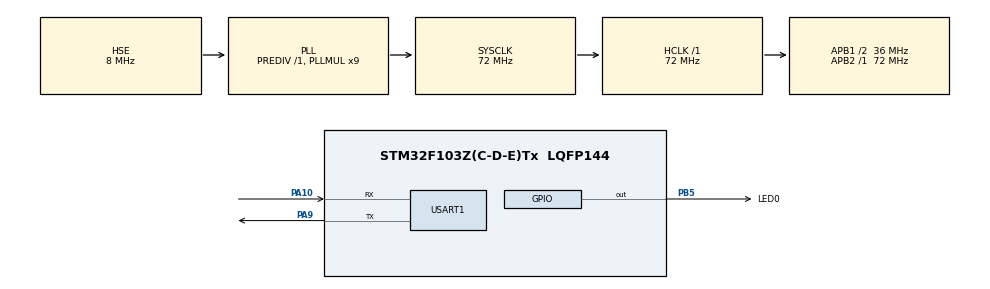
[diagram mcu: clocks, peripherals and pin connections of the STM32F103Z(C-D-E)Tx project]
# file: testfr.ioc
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FREERTOS.Tasks01=defaultTask,24,128,StartDefaultTask,Default,NULL,Dynamic,NULL,NULL
Mcu.Family=STM32F1
Mcu.Name=STM32F103Z(C-D-E)Tx
Mcu.Package=LQFP144
NVIC.PriorityGroup=NVIC_PRIORITYGROUP_4
NVIC.TIM4_IRQn=true\:15\:0\:false\:false\:true\:false\:false\:true\:true
NVIC.TimeBase=TIM4_IRQn
NVIC.TimeBaseIP=TIM4
NVIC.USART1_IRQn=true\:5\:0\:false\:false\:true\:true\:true\:true\:true
OSC_IN.Mode=HSE-External-Oscillator
OSC_IN.Signal=RCC_OSC_IN
OSC_OUT.Mode=HSE-External-Oscillator
OSC_OUT.Signal=RCC_OSC_OUT
PA10.Mode=Asynchronous
PA10.Signal=USART1_RX
PA13.Mode=Serial_Wire
PA13.Signal=SYS_JTMS-SWDIO
PA14.Mode=Serial_Wire
PA14.Signal=SYS_JTCK-SWCLK
PA9.Mode=Asynchronous
PA9.Signal=USART1_TX
PB5.GPIO_Label=LED0
PB5.Signal=GPIO_Output
ProjectManager.HeapSize=0x200
ProjectManager.StackSize=0x400
ProjectManager.TargetToolchain=Makefile
RCC.AHBFreq_Value=72000000
RCC.APB1CLKDivider=RCC_HCLK_DIV2
RCC.APB1Freq_Value=36000000
RCC.APB1TimFreq_Value=72000000
RCC.APB2Freq_Value=72000000
RCC.APB2TimFreq_Value=72000000
RCC.HCLKFreq_Value=72000000
RCC.PLLMUL=RCC_PLL_MUL9
RCC.PLLSourceVirtual=RCC_PLLSOURCE_HSE
RCC.SYSCLKFreq_VALUE=72000000
RCC.SYSCLKSource=RCC_SYSCLKSOURCE_PLLCLK
RCC.USBFreq_Value=72000000
USART1.VirtualMode=VM_ASYNC
VP_FREERTOS_VS_CMSIS_V2.Mode=CMSIS_V2
VP_SYS_VS_tim4.Mode=TIM4
board=custom

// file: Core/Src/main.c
/* USER CODE BEGIN Header */
/**
 ******************************************************************************
 * @file           : main.c
 * @brief          : Main program body
 ******************************************************************************
 * @attention
 *
 * Copyright (c) 2026 STMicroelectronics.
 * All rights reserved.
 *
 * This software is licensed under terms that can be found in the LICENSE file
 * in the root directory of this software component.
 * If no LICENSE file comes with this software, it is provided AS-IS.
 *
 ******************************************************************************
 */
/* USER CODE END Header */
#include "main.h"
#include "cmsis_os.h"
#include "usart.h"
#include "gpio.h"

/* USER CODE BEGIN Includes */
#include "iwdg_drv.h"
#include "rtc_drv.h"
/* USER CODE END Includes */

void SystemClock_Config(void);
void MX_FREERTOS_Init(void);

int main(void)
{

  /* USER CODE BEGIN 1 */
  SCB->VTOR = 0x08008000;
  /* USER CODE END 1 */

  /* MCU Configuration--------------------------------------------------------*/

  /* Reset of all peripherals, Initializes the Flash interface and the Systick. */
  HAL_Init();

  /* Configure the system clock */
  SystemClock_Config();

  /* Initialize all configured peripherals */
  MX_GPIO_Init();
  MX_USART1_UART_Init();
  /* USER CODE BEGIN 2 */
  IWDG_DRV_Init(2); /* Start independent watchdog (2s timeout) */
  /* USER CODE END 2 */
  /* RTC: only set time on first boot (backup domain lost) */
  if (RTC_DRV_Init() != HAL_OK)
  {
    RTC_DRV_SetDate(26, 6, 1, 0); /* 2026-06-01 Sunday */
    RTC_DRV_SetTime(21, 20, 0);   /* 21:18:00 */
  }
  /* Init scheduler */
  osKernelInitialize();

  /* Call init function for freertos objects (in cmsis_os2.c) */
  MX_FREERTOS_Init();

  /* Start scheduler */
  osKernelStart();

  /* We should never get here as control is now taken by the scheduler */

  /* Infinite loop */
  while (1)
  {

  }
}

void SystemClock_Config(void)
{
  RCC_OscInitTypeDef RCC_OscInitStruct = {0};
  RCC_ClkInitTypeDef RCC_ClkInitStruct = {0};

  /** Initializes the RCC Oscillators according to the specified parameters
   * in the RCC_OscInitTypeDef structure.
   */
  RCC_OscInitStruct.OscillatorType = RCC_OSCILLATORTYPE_HSE;
  RCC_OscInitStruct.HSEState = RCC_HSE_ON;
  RCC_OscInitStruct.HSEPredivValue = RCC_HSE_PREDIV_DIV1;
  RCC_OscInitStruct.HSIState = RCC_HSI_ON;
  RCC_OscInitStruct.PLL.PLLState = RCC_PLL_ON;
  RCC_OscInitStruct.PLL.PLLSource = RCC_PLLSOURCE_HSE;
  RCC_OscInitStruct.PLL.PLLMUL = RCC_PLL_MUL9;
  if (HAL_RCC_OscConfig(&RCC_OscInitStruct) != HAL_OK)
  {
    Error_Handler();
  }

  /** Initializes the CPU, AHB and APB buses clocks
   */
  RCC_ClkInitStruct.ClockType = RCC_CLOCKTYPE_HCLK | RCC_CLOCKTYPE_SYSCLK | RCC_CLOCKTYPE_PCLK1 | RCC_CLOCKTYPE_PCLK2;
  RCC_ClkInitStruct.SYSCLKSource = RCC_SYSCLKSOURCE_PLLCLK;
  RCC_ClkInitStruct.AHBCLKDivider = RCC_SYSCLK_DIV1;
  RCC_ClkInitStruct.APB1CLKDivider = RCC_HCLK_DIV2;
  RCC_ClkInitStruct.APB2CLKDivider = RCC_HCLK_DIV1;

  if (HAL_RCC_ClockConfig(&RCC_ClkInitStruct, FLASH_LATENCY_2) != HAL_OK)
  {
    Error_Handler();
  }
}

void HAL_TIM_PeriodElapsedCallback(TIM_HandleTypeDef *htim)
{
  if (htim->Instance == TIM4)
  {
    HAL_IncTick();
  }
}

void Error_Handler(void)
{
  __disable_irq();
  while (1)
  {
  }
}

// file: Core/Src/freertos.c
/* USER CODE BEGIN Header */
/**
 ******************************************************************************
 * File Name          : freertos.c
 * Description        : Code for freertos applications
 ******************************************************************************
 * @attention
 *
 * Copyright (c) 2026 STMicroelectronics.
 * All rights reserved.
 *
 * This software is licensed under terms that can be found in the LICENSE file
 * in the root directory of this software component.
 * If no LICENSE file comes with this software, it is provided AS-IS.
 *
 ******************************************************************************
 */
/* USER CODE END Header */

#include "FreeRTOS.h"
#include "task.h"
#include "main.h"
#include "cmsis_os.h"

/* USER CODE BEGIN Includes */
#include "key.h"
#include "usart.h"
#include "app_temp.h"
#include "app_lcd.h"
#include "iwdg_drv.h"
#include "cmsis_os2.h"
#include "breath_led.h"
#include "app_eeprom.h"
#include <stdio.h>
/* USER CODE END Includes */

/* USER CODE BEGIN Variables */
osMessageQueueId_t keyQueueHandle;
osMessageQueueAttr_t keyQueue_attributes = {
    .name = "keyQueue"
};

osMessageQueueId_t eepromQueueHandle;
osMessageQueueAttr_t eepromQueue_attributes = {
    .name = "eepromQueue"
};
/* USER CODE END Variables */
/* Definitions for defaultTask */
osThreadId_t defaultTaskHandle;
const osThreadAttr_t defaultTask_attributes = {
    .name = "defaultTask",
    .stack_size = 128 * 4,
    .priority = (osPriority_t)osPriorityNormal,
};

/* Definitions for keyTask */
osThreadId_t keyTaskHandle;
const osThreadAttr_t keyTask_attributes = {
    .name = "keyTask",
    .stack_size = 128 * 4,
    .priority = (osPriority_t)osPriorityNormal,
};
/* Definitions for tempTask */
osThreadId_t tempTaskHandle;
const osThreadAttr_t tempTask_attributes = {
    .name = "tempTask",
    .stack_size = 256 * 4,
    .priority = (osPriority_t)osPriorityLow,
};
/* Definitions for lcdTask */
osThreadId_t lcdTaskHandle;
const osThreadAttr_t lcdTask_attributes = {
    .name = "lcdTask",
    .stack_size = 512 * 4,
    .priority = (osPriority_t)osPriorityNormal,
};
/* Definitions for eepromTask */
osThreadId_t eepromTaskHandle;
const osThreadAttr_t eepromTask_attributes = {
    .name = "eepromTask",
    .stack_size = 128 * 4,
    .priority = (osPriority_t)osPriorityNormal,
};

void StartDefaultTask(void *argument);
void StartKeyTask(void *argument);
void StartTempTask(void *argument);
void StartLcdTask(void *argument);
void StartEepromTask(void *argument);

void MX_FREERTOS_Init(void); /* (MISRA C 2004 rule 8.1) */

void MX_FREERTOS_Init(void)
{

  /* Create the thread(s) */
  /* creation of defaultTask */
  defaultTaskHandle = osThreadNew(StartDefaultTask, NULL, &defaultTask_attributes);

  /* creation of keyTask */
  keyTaskHandle = osThreadNew(StartKeyTask, NULL, &keyTask_attributes);

  /* creation of tempTask */
  tempTaskHandle = osThreadNew(StartTempTask, NULL, &tempTask_attributes);

  /* creation of lcdTask */
  lcdTaskHandle = osThreadNew(StartLcdTask, NULL, &lcdTask_attributes);

  /* creation of keyQueue */
  keyQueueHandle = osMessageQueueNew(10, sizeof(uint8_t), &keyQueue_attributes);

  /* creation of eepromTask */
  eepromTaskHandle = osThreadNew(StartEepromTask, NULL, &eepromTask_attributes);

  /* creation of eepromQueue */
  eepromQueueHandle = osMessageQueueNew(10, sizeof(uint8_t), &eepromQueue_attributes);

}

void StartDefaultTask(void *argument)
{
  /* USER CODE BEGIN StartDefaultTask */
  IWDG_DRV_Feed(); /* feed as early as possible */
  setvbuf(stdout, NULL, _IONBF, 0);
  printf("System initialized, FreeRTOS running!\r\n");

  BL_Init();
  BL_SetPeriod_ms(3000); /* 呼吸周期 2.5 秒 */
  BL_SetGamma(0.8f);     /* gamma 校正 0.8 */

  uint32_t wdg_last = osKernelGetTickCount();
  uint32_t now;

  for (;;)
  {
    now = osKernelGetTickCount();

    /* 每 10ms 更新呼吸灯，保证平滑过渡 */
    BL_Process();

    if (now - wdg_last >= 500)
    {
      IWDG_DRV_Feed();
      wdg_last = now;
    }

    if (uart1_data_ready())
    {
      printf("%s", (char *)uart1_rx_buf);
      USART1_StartRx();
    }

    osDelay(1); /* yield to scheduler */
  }
  /* USER CODE END StartDefaultTask */
}

void StartKeyTask(void *argument)
{
  /* USER CODE BEGIN StartKeyTask */
  /* Infinite loop */
  for (;;)
  {
    Key_Process();
    osDelay(10);
  }
  /* USER CODE END StartKeyTask */
}
